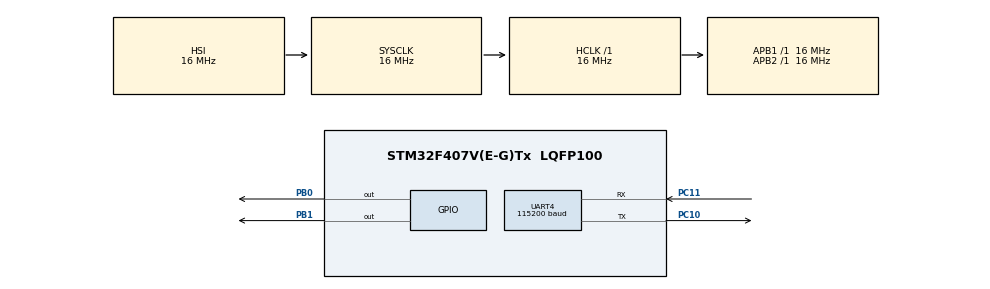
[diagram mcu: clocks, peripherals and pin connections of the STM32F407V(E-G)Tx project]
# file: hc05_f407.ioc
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Mcu.Family=STM32F4
Mcu.Name=STM32F407V(E-G)Tx
Mcu.Package=LQFP100
NVIC.PriorityGroup=NVIC_PRIORITYGROUP_4
NVIC.UART4_IRQn=true\:0\:0\:false\:false\:true\:true\:true\:true
PA13.Mode=Serial_Wire
PA13.Signal=SYS_JTMS-SWDIO
PA14.Mode=Serial_Wire
PA14.Signal=SYS_JTCK-SWCLK
PB0.Signal=GPIO_Output
PB1.Signal=GPIO_Output
PC10.Mode=Asynchronous
PC10.Signal=UART4_TX
PC11.Mode=Asynchronous
PC11.Signal=UART4_RX
PH0-OSC_IN.Mode=HSE-External-Oscillator
PH0-OSC_IN.Signal=RCC_OSC_IN
PH1-OSC_OUT.Mode=HSE-External-Oscillator
PH1-OSC_OUT.Signal=RCC_OSC_OUT
ProjectManager.HeapSize=0x200
ProjectManager.StackSize=0x400
ProjectManager.TargetToolchain=MDK-ARM V5
RCC.AHBFreq_Value=16000000
RCC.APB1Freq_Value=16000000
RCC.APB2Freq_Value=16000000
RCC.CortexFreq_Value=16000000
RCC.HSE_VALUE=25000000
RCC.HSI_VALUE=16000000
RCC.LSE_VALUE=32768
RCC.SYSCLKFreq_VALUE=16000000
RCC.VCOOutputFreq_Value=192000000
UART4.BaudRate=115200
UART4.VirtualMode=Asynchronous
board=custom

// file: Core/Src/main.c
/* USER CODE BEGIN Header */
/**
  ******************************************************************************
  * @file           : main.c
  * @brief          : Main program body
  ******************************************************************************
  * @attention
  *
  * Copyright (c) 2026 STMicroelectronics.
  * All rights reserved.
  *
  * This software is licensed under terms that can be found in the LICENSE file
  * in the root directory of this software component.
  * If no LICENSE file comes with this software, it is provided AS-IS.
  *
  ******************************************************************************
  */
/* USER CODE END Header */
#include "main.h"

/* USER CODE BEGIN Includes */
#include "hc05_node.h"
/* USER CODE END Includes */

UART_HandleTypeDef huart4;

void SystemClock_Config(void);
static void MX_GPIO_Init(void);
static void MX_UART4_Init(void);

int main(void)
{

  /* MCU Configuration--------------------------------------------------------*/

  /* Reset of all peripherals, Initializes the Flash interface and the Systick. */
  HAL_Init();

  /* Configure the system clock */
  SystemClock_Config();

  /* Initialize all configured peripherals */
  MX_GPIO_Init();
  MX_UART4_Init();
  /* USER CODE BEGIN 2 */
  /* Briefly light both active-low user LEDs, then start the HC-05 node. */
  HAL_GPIO_WritePin(HC05_LINK_LED_GPIO_Port, HC05_LINK_LED_Pin, GPIO_PIN_RESET);
  HAL_GPIO_WritePin(HC05_ACTIVITY_LED_GPIO_Port, HC05_ACTIVITY_LED_Pin, GPIO_PIN_RESET);
  HAL_Delay(150);
  HAL_GPIO_WritePin(HC05_LINK_LED_GPIO_Port, HC05_LINK_LED_Pin, GPIO_PIN_SET);
  HAL_GPIO_WritePin(HC05_ACTIVITY_LED_GPIO_Port, HC05_ACTIVITY_LED_Pin, GPIO_PIN_SET);
  hc05_node_init(&huart4);
  /* USER CODE END 2 */

  /* Infinite loop */
  while (1)
  {

    /* USER CODE BEGIN 3 */
    hc05_node_process(HAL_GetTick());
  }
  /* USER CODE END 3 */
}

void SystemClock_Config(void)
{
  RCC_OscInitTypeDef RCC_OscInitStruct = {0};
  RCC_ClkInitTypeDef RCC_ClkInitStruct = {0};

  /** Configure the main internal regulator output voltage
  */
  __HAL_RCC_PWR_CLK_ENABLE();
  __HAL_PWR_VOLTAGESCALING_CONFIG(PWR_REGULATOR_VOLTAGE_SCALE1);

  /** Initializes the RCC Oscillators according to the specified parameters
  * in the RCC_OscInitTypeDef structure.
  */
  RCC_OscInitStruct.OscillatorType = RCC_OSCILLATORTYPE_HSI;
  RCC_OscInitStruct.HSIState = RCC_HSI_ON;
  RCC_OscInitStruct.HSICalibrationValue = RCC_HSICALIBRATION_DEFAULT;
  RCC_OscInitStruct.PLL.PLLState = RCC_PLL_NONE;
  if (HAL_RCC_OscConfig(&RCC_OscInitStruct) != HAL_OK)
  {
    Error_Handler();
  }

  /** Initializes the CPU, AHB and APB buses clocks
  */
  RCC_ClkInitStruct.ClockType = RCC_CLOCKTYPE_HCLK|RCC_CLOCKTYPE_SYSCLK
                              |RCC_CLOCKTYPE_PCLK1|RCC_CLOCKTYPE_PCLK2;
  RCC_ClkInitStruct.SYSCLKSource = RCC_SYSCLKSOURCE_HSI;
  RCC_ClkInitStruct.AHBCLKDivider = RCC_SYSCLK_DIV1;
  RCC_ClkInitStruct.APB1CLKDivider = RCC_HCLK_DIV1;
  RCC_ClkInitStruct.APB2CLKDivider = RCC_HCLK_DIV1;

  if (HAL_RCC_ClockConfig(&RCC_ClkInitStruct, FLASH_LATENCY_0) != HAL_OK)
  {
    Error_Handler();
  }
}

static void MX_UART4_Init(void)
{

  huart4.Instance = UART4;
  huart4.Init.BaudRate = 115200;
  huart4.Init.WordLength = UART_WORDLENGTH_8B;
  huart4.Init.StopBits = UART_STOPBITS_1;
  huart4.Init.Parity = UART_PARITY_NONE;
  huart4.Init.Mode = UART_MODE_TX_RX;
  huart4.Init.HwFlowCtl = UART_HWCONTROL_NONE;
  huart4.Init.OverSampling = UART_OVERSAMPLING_16;
  if (HAL_UART_Init(&huart4) != HAL_OK)
  {
    Error_Handler();
  }

}

static void MX_GPIO_Init(void)
{
  GPIO_InitTypeDef GPIO_InitStruct = {0};

  /* GPIO Ports Clock Enable */
  __HAL_RCC_GPIOH_CLK_ENABLE();
  __HAL_RCC_GPIOB_CLK_ENABLE();
  __HAL_RCC_GPIOA_CLK_ENABLE();
  __HAL_RCC_GPIOC_CLK_ENABLE();

  /*Configure GPIO pin Output Level */
  HAL_GPIO_WritePin(GPIOB, GPIO_PIN_0|GPIO_PIN_1, GPIO_PIN_RESET);

  /*Configure GPIO pins : PB0 PB1 */
  GPIO_InitStruct.Pin = GPIO_PIN_0|GPIO_PIN_1;
  GPIO_InitStruct.Mode = GPIO_MODE_OUTPUT_PP;
  GPIO_InitStruct.Pull = GPIO_NOPULL;
  GPIO_InitStruct.Speed = GPIO_SPEED_FREQ_LOW;
  HAL_GPIO_Init(GPIOB, &GPIO_InitStruct);

}

/* USER CODE BEGIN 4 */
void HAL_UART_RxCpltCallback(UART_HandleTypeDef *uart)
{
  hc05_node_rx_complete_isr(uart);
}

void HAL_UART_ErrorCallback(UART_HandleTypeDef *uart)
{
  hc05_node_error_isr(uart);
}
/* USER CODE END 4 */

void Error_Handler(void)
{
  __disable_irq();
  while (1)
  {
  }
}
